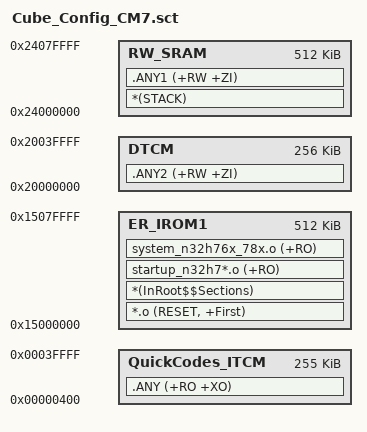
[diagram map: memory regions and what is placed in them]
; *************************************************************
; *** Scatter-Loading Description File generated by uVision ***
; *************************************************************

; *** NTFx CODE START  ***
LR_IROM1 0x15000000 0x80000   {    ; load region size_region
  ER_IROM1 0x15000000  0x80000   {  ; load address = execution address
   *.o (RESET, +First)         ; Reset vector table
   *(InRoot$$Sections)         ; All library sections that must be in a root region, 
                               ;for example, __main.o, __scatter*.o, __dc*.o, and * Region$$Table
   startup_n32h7*.o (+RO)
   system_n32h76x_78x.o (+RO)

  }
  QuickCodes_ITCM  0x400  0x3fc00   {  ;  offset 0x400 for VECTOR TABLE
   .ANY (+RO +XO)
  }
  RW_SRAM 0x24000000  0x80000   { 
   *(STACK)
   .ANY1 (+RW +ZI) 
  }
  DTCM  0x20000000  0x40000   {  
   .ANY2 (+RW +ZI)              ;ANYx: The larger the x, the higher the priority
  }
; *** NTFx CODE END  ***
}
